# MU3E_FULL8LANE_TYPE0_SYSTEM_SC_HUB register map
Vendor: Mu3e; Series: MU3E_FULL8LANE_TYPE0; File version: 2026.05.06
Registers are 32-bit, read-write, reset 0x0 unless marked. A register's access mark holds for its fields unless they carry their own. Offsets are from the block's base; [hi:lo] are bit positions; {n}, {i} and the like mark numbered series.

## DATA_PATH_SUBSYSTEM_BACKPRESSURE_FIFO_0_CSR — Datapath-local slave expanded below the SC-hub mm_bridge.s0 aperture. Qsys slave data_path_subsystem_backpressure_fifo_0.csr is SC-hub-relative at 0x00020860 with compiled aperture size 0x00000010. Compiled Qsys module backpressure_fifo_0 kind=altera_avalon_sc_fifo version=18.1 from full8lane_type0_datapath.qsys. Source SVD toolkits/infra/cmsis_svd/generic/backpressure_fifo_window.svd version 1.0.0. Relative 4-word backpressure FIFO status aperture.
Base 0x00020860
Same registers: DATA_PATH_SUBSYSTEM_BACKPRESSURE_FIFO_1_CSR 0x00021860, DATA_PATH_SUBSYSTEM_BACKPRESSURE_FIFO_2_CSR 0x00022860, DATA_PATH_SUBSYSTEM_BACKPRESSURE_FIFO_3_CSR 0x00023860, DATA_PATH_SUBSYSTEM_BACKPRESSURE_FIFO_4_CSR 0x00024860, DATA_PATH_SUBSYSTEM_BACKPRESSURE_FIFO_5_CSR 0x00025860, DATA_PATH_SUBSYSTEM_BACKPRESSURE_FIFO_6_CSR 0x00026860, DATA_PATH_SUBSYSTEM_BACKPRESSURE_FIFO_7_CSR 0x00027860
{0x0+4i} WORD{i:03} ro (i=0..3) — Backpressure FIFO CSR word {i}.
  [31:0] value — Raw backpressure FIFO CSR word {i}.

## DATA_PATH_SUBSYSTEM_MUTRIG_FRAME_DEASSEMBLY_0_CSR — Datapath-local slave expanded below the SC-hub mm_bridge.s0 aperture. Qsys slave data_path_subsystem_mutrig_frame_deassembly_0.csr is SC-hub-relative at 0x00020900 with compiled aperture size 0x00000010. Compiled Qsys module mutrig_frame_deassembly_0 kind=mutrig_frame_deassembly version=26.0.6.418 from full8lane_type0_datapath.qsys. Version/identity parameters: VERSION_MAJOR=26, VERSION_MINOR=0, VERSION_PATCH=6, BUILD=418, VERSION_DATE=20260418, VERSION_GIT=0, IP_UID=1179804502, INSTANCE_ID=0. Source SVD mutrig_frame_deassembly/script/mutrig_frame_deassembly.svd version 26.0.6.0418. Relative 4-word CSR aperture for MuTRiG frame deassembly.
Base 0x00020900
Same registers: DATA_PATH_SUBSYSTEM_MUTRIG_FRAME_DEASSEMBLY_1_CSR 0x00021900, DATA_PATH_SUBSYSTEM_MUTRIG_FRAME_DEASSEMBLY_2_CSR 0x00022900, DATA_PATH_SUBSYSTEM_MUTRIG_FRAME_DEASSEMBLY_3_CSR 0x00023900, DATA_PATH_SUBSYSTEM_MUTRIG_FRAME_DEASSEMBLY_4_CSR 0x00024900, DATA_PATH_SUBSYSTEM_MUTRIG_FRAME_DEASSEMBLY_5_CSR 0x00025900, DATA_PATH_SUBSYSTEM_MUTRIG_FRAME_DEASSEMBLY_6_CSR 0x00026900, DATA_PATH_SUBSYSTEM_MUTRIG_FRAME_DEASSEMBLY_7_CSR 0x00027900
{0x0+4i} WORD{i:03} ro (i=0..3) — MuTRiG frame deassembly CSR word {i}.
  [31:0] value — Raw MuTRiG frame deassembly CSR word {i}.

## DATA_PATH_SUBSYSTEM_EMULATOR_MUTRIG_0_CSR — Datapath-local slave expanded below the SC-hub mm_bridge.s0 aperture. Qsys slave data_path_subsystem_emulator_mutrig_0.csr is SC-hub-relative at 0x00022000 with compiled aperture size 0x00000040. Compiled Qsys module emulator_mutrig_0 kind=emulator_mutrig version=26.2.0.502 from full8lane_type0_datapath.qsys. Version/identity parameters: VERSION_MAJOR=26, VERSION_MINOR=2, VERSION_PATCH=0, BUILD=502, VERSION_DATE=20260502, VERSION_GIT=179563176, IP_UID=1162696020, INSTANCE_ID=0. Source SVD emulator_mutrig/emulator_mutrig.svd version 26.1.13.0425. Relative 16-word configuration and status window for one emulator instance.
Base 0x00022000
Same registers: DATA_PATH_SUBSYSTEM_EMULATOR_MUTRIG_1_CSR 0x00022040, DATA_PATH_SUBSYSTEM_EMULATOR_MUTRIG_2_CSR 0x00022080, DATA_PATH_SUBSYSTEM_EMULATOR_MUTRIG_3_CSR 0x000220C0, DATA_PATH_SUBSYSTEM_EMULATOR_MUTRIG_4_CSR 0x00022100, DATA_PATH_SUBSYSTEM_EMULATOR_MUTRIG_5_CSR 0x00022140, DATA_PATH_SUBSYSTEM_EMULATOR_MUTRIG_6_CSR 0x00022180, DATA_PATH_SUBSYSTEM_EMULATOR_MUTRIG_7_CSR 0x000221C0
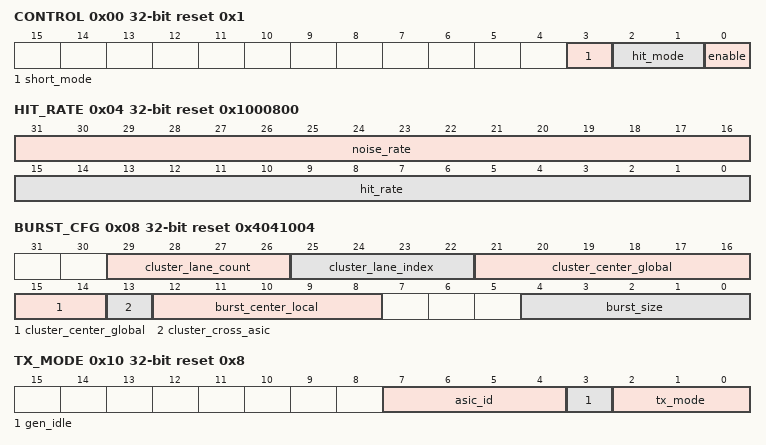
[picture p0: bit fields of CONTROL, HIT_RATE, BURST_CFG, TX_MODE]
0x00 CONTROL reset 0x1 — Main emulator enable and hit-generation mode.
  [3] short_mode — 1 selects short frame interval; 0 selects long frame interval.
  [2:1] hit_mode — 0=legacy folded Poisson, 1=burst/injected cluster replay, 2=folded per-channel IID Poisson, 3=folded per-channel periodic.
  [0] enable — Enable hit generation/output.
0x04 HIT_RATE reset 0x1000800 — Fixed-point hit and noise rates.
  [31:16] noise_rate — 8.8 fixed-point noise-rate control.
  [15:0] hit_rate — 8.8 fixed-point hit-rate control.
0x08 BURST_CFG reset 0x4041004 — Burst and multi-ASIC cluster configuration.
  [29:26] cluster_lane_count — Number of lanes in the shared cluster domain.
  [25:22] cluster_lane_index — Lane index inside the shared cluster domain.
  [21:14] cluster_center_global — Global cluster center when cross-ASIC mode is enabled.
  [13] cluster_cross_asic — Enable shared global cluster across ASIC lanes.
  [12:8] burst_center_local — Local 32-channel burst center.
  [4:0] burst_size — Local burst size.
0x0C PRNG_SEED reset 0xDEADBEEF — Hit generator PRNG seed.
  [31:0] seed — 32-bit PRNG seed.
0x10 TX_MODE reset 0x8 — Frame output mode and ASIC channel tag.
  [7:4] asic_id — ASIC ID/channel tag, clamped to 0..7 by RTL.
  [3] gen_idle — Generate idle words when enabled.
  [2:0] tx_mode — Frame assembler TX mode.
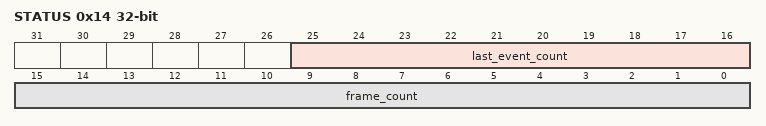
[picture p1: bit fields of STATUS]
0x14 STATUS ro — Frame and event counters captured at frame start.
  [25:16] last_event_count — Last event count captured at frame start.
  [15:0] frame_count — Frame-start counter.
0x18 INJECT_MASK reset 0xFFFFFFFF — Masked injection channel participation mask.
  [31:0] channel_mask — Bit N enables channel N for masked injection triggers.
